# K1921VK028 register map
Vendor: NIIET; Series: K1921VKx; File version: 2.17
CPU: CM4 r0p1, little endian, MPU, FPU, 4 interrupt priority bits
Registers are 32-bit, read-write, reset 0x0 unless marked. A register's access mark holds for its fields unless they carry their own. Offsets are from the block's base; [hi:lo] are bit positions; {n}, {i} and the like mark numbered series.

## TUART0 — Tiny UART control registers
Base 0x40089000
Same registers: TUART1 0x4008A000
0x00 DATA — Data value register
  [7:0] VAL
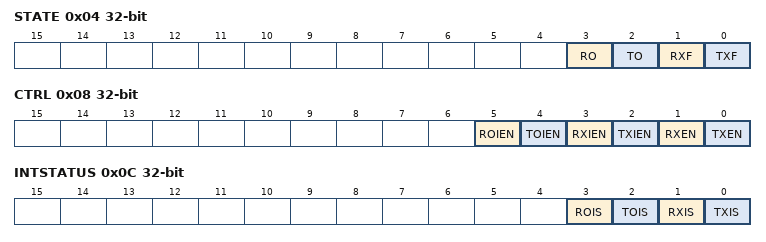
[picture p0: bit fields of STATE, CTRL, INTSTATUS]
0x04 STATE
  [3] RO — RX buffer overrun
  [2] TO — TX buffer overrun
  [1] RXF ro — RX buffer full
  [0] TXF ro — TX buffer full
0x08 CTRL — Control register
  [5] ROIEN — RX overrun interrupt enable
  [4] TOIEN — TX overrun interrupt enable
  [3] RXIEN — RX interrupt enable
  [2] TXIEN — TX interrupt enable
  [1] RXEN — RX enable
  [0] TXEN — TX enable
0x0C INTSTATUS — Interrupt status register
  [3] ROIS — RX overrun interrupt status
  [2] TOIS — TX overrun interrupt status
  [1] RXIS — RX interrupt status
  [0] TXIS — TX interrupt status
0x10 BAUDDIV — Baudrate Divider register
  [19:0] VAL

## OWI0 — OWI control registers
Base 0x400AF000
Same registers: OWI1 0x400B0000
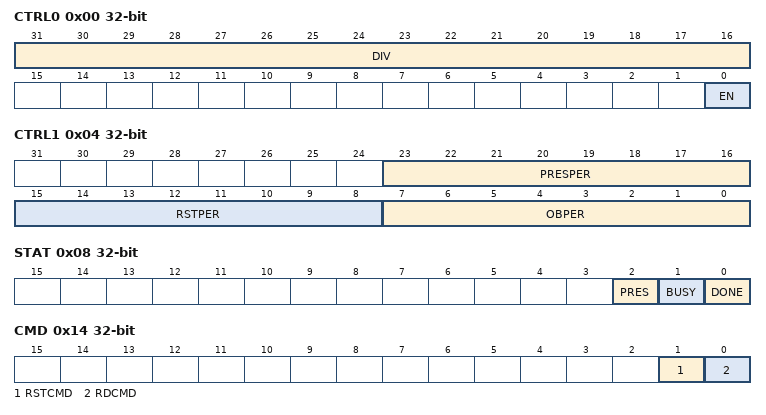
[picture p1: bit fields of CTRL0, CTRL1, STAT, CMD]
0x00 CTRL0 — Control 0 Register
  [31:16] DIV — Clock divider value for one tick
  [0] EN — Enable OWI
0x04 CTRL1 — Control 1 Register
  [23:16] PRESPER — Presence period in ticks
  [15:8] RSTPER — Reset period in ticks
  [7:0] OBPER — One bit period in ticks
0x08 STAT — Status register
  [2] PRES ro — Presence flag status after reset sequence
  [1] BUSY ro — Busy flag status
  [0] DONE — Operation DONE Flag for interrupt
0x0C IRQ — Interrupt Control Register
  [0] EN — Enable interrupt DONE operation
0x10 DATA
  [7:0] DATA — Data register. On write - init tx write operation. On read - get read value after RDCMD done.
0x14 CMD wo — Command Regiser
  [1] RSTCMD — Initialize reset sequence command
  [0] RDCMD — Initialize read command

## DMA — DMA control registers
Base 0x40084000
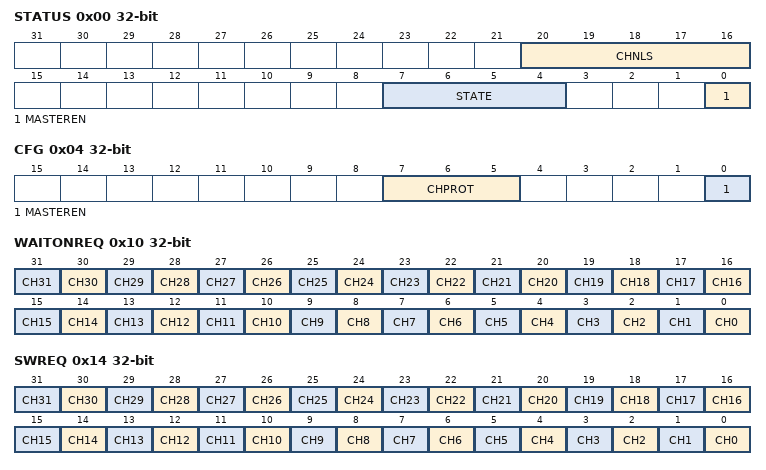
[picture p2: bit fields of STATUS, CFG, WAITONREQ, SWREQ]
0x00 STATUS ro — Status DMA register
  [20:16] CHNLS — Number channel DMA (write: N-1)
  [7:4] STATE — State of DMA
    on read: 0=Free (At rest); 1=ReadConfigData (Reading the config data structure); 2=ReadSrcDataEndPtr (Reading sourse data end pointer); 3=ReadDstDataEndPtr (Reading destination data end pointer); 4=ReadSrcData (Reading source data); 5=WrireDstData (Writing data to the destination); 6=WaitReq (Waiting for a request); 7=WriteConfigData (Write config structure of the channel); 8=Pause (Suspended); 9=Done (Executed); 10=PeriphScatGath (mode "peripheral scather-gather")
  [0] MASTEREN — Indicate enable DMA
0x04 CFG wo — DMA configuration register
  [7:5] CHPROT — Sets the AHB-Lite protection
  [0] MASTEREN — Enable DMA
0x08 BASEPTR — Channel control data base pointer
  [31:0] VAL
0x0C ALTBASEPTR ro — Channel alternate control data base pointer
  [31:0] VAL
0x10 WAITONREQ ro — Channel wait on request status
  [n] CH{n} (n=0..31) — Returns the status of the DMA request signals
0x14 SWREQ wo — Channel software request
  [n] CH{n} (n=0..31) — Set software request on channel
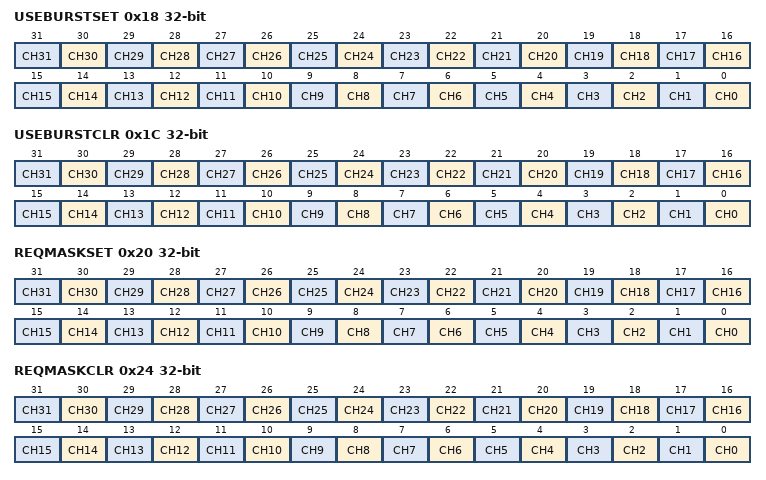
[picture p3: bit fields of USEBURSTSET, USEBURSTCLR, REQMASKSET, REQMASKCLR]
0x18 USEBURSTSET — Channel useburst set
  [n] CH{n} (n=0..31) — Enable single requests
0x1C USEBURSTCLR wo — Channel useburst clear
  [n] CH{n} (n=0..31) — Disable single requests
0x20 REQMASKSET — Channel request mask set
  [n] CH{n} (n=0..31) — External requests are enabled for channel
0x24 REQMASKCLR wo — Channel request mask clear
  [n] CH{n} (n=0..31) — External requests are disabled for channel
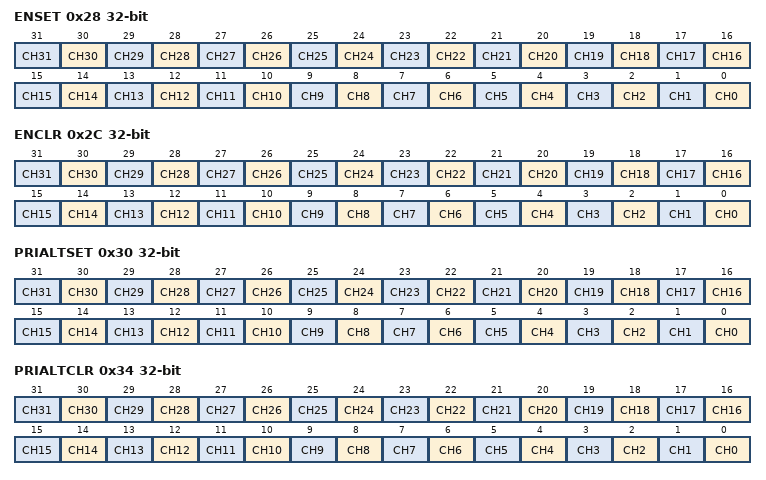
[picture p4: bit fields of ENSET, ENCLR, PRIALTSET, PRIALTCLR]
0x28 ENSET — Channel enable set
  [n] CH{n} (n=0..31) — Enable channel
0x2C ENCLR wo — Channel enable clear
  [n] CH{n} (n=0..31) — Disable channel
0x30 PRIALTSET — Channel primary-alternate set
  [n] CH{n} (n=0..31) — Set primary / alternate channel control data structure
0x34 PRIALTCLR wo — Channel primary-alternate clear
  [n] CH{n} (n=0..31) — Clear primary / alternate channel control data structure
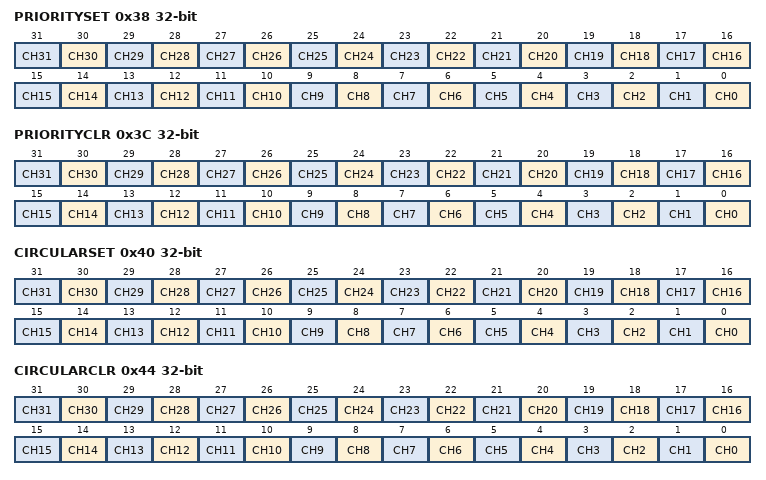
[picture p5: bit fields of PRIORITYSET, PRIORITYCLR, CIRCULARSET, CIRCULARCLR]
0x38 PRIORITYSET — Channel priority set
  [n] CH{n} (n=0..31) — Set the priority of channel
0x3C PRIORITYCLR wo — Channel priority clear
  [n] CH{n} (n=0..31) — Clear the priority
0x40 CIRCULARSET — Channel circular set
  [n] CH{n} (n=0..31) — Set the channel circular mode
0x44 CIRCULARCLR wo — Channel circular clear
  [n] CH{n} (n=0..31) — Clear the channel circular mode
0x4C ERRCLR — Bus error register
  [0] VAL — Indicate Error on bus AHB-Lite
